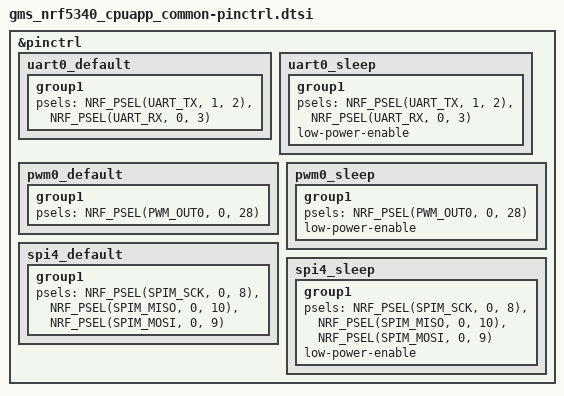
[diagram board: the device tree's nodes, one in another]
/*
 * Copyright (c) 2023 Raytac Corporation
 *
 * SPDX-License-Identifier: Apache-2.0
 */

&pinctrl {
	uart0_default: uart0_default {
		group1 {
			psels = <NRF_PSEL(UART_TX, 1, 2)>,
				<NRF_PSEL(UART_RX, 0, 3)>;
		};
	};

	uart0_sleep: uart0_sleep {
		group1 {
			psels = <NRF_PSEL(UART_TX, 1, 2)>,
				<NRF_PSEL(UART_RX, 0, 3)>;
			low-power-enable;
		};
	};

	pwm0_default: pwm0_default {
		group1 {
			psels = <NRF_PSEL(PWM_OUT0, 0, 28)>;
		};
	};

	pwm0_sleep: pwm0_sleep {
		group1 {
			psels = <NRF_PSEL(PWM_OUT0, 0, 28)>;
			low-power-enable;
		};
	};


	spi4_default: spi4_default {
		group1 {
			psels = <NRF_PSEL(SPIM_SCK, 0, 8)>,
				<NRF_PSEL(SPIM_MISO, 0, 10)>,
				<NRF_PSEL(SPIM_MOSI, 0, 9)>;
		};
	};

	spi4_sleep: spi4_sleep {
		group1 {
			psels = <NRF_PSEL(SPIM_SCK, 0, 8)>,
				<NRF_PSEL(SPIM_MISO, 0, 10)>,
				<NRF_PSEL(SPIM_MOSI, 0, 9)>;
			low-power-enable;
		};
	};

};
